# R40 register map
Vendor: Allwinner; Series: R40; File version: 0.1
CPU: CA7 0, little endian, MPU, FPU, double-precision FPU, 0 interrupt priority bits
Registers are 32-bit, read-write, reset 0x0 unless marked. A register's access mark holds for its fields unless they carry their own. Offsets are from the block's base; [hi:lo] are bit positions; {n}, {i} and the like mark numbered series; 'fields as' and 'values as' point back to an identical list.

## Timer
Base 0x01C20C00
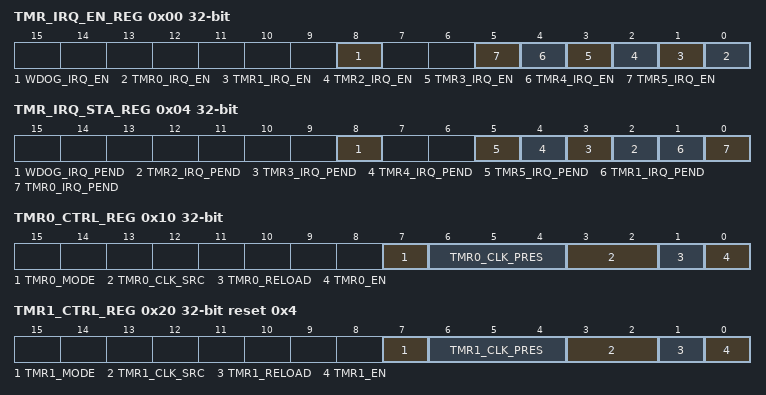
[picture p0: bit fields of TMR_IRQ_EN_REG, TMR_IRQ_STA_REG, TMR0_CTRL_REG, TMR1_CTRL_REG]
0x00 TMR_IRQ_EN_REG — Timer IRQ Enable Register
  [8] WDOG_IRQ_EN — Watchdog Interrupt Enable. 0: No effect 1: Watchdog Interval Value reached interrupt enable.
    0=No_effect; 1=Watchdog Interval Value reached interrupt enable
  [n] TMR{n}_IRQ_EN (n=0..5) — Timer {n} Interrupt Enable. 0: No effect 1: Timer {n} Interval Value reached interrupt enable.
    0=No_effect; 1=Timer {n} Interval Value reached interrupt enable
0x04 TMR_IRQ_STA_REG reset not defined — 0x0004 Timer Status Register
  [8] WDOG_IRQ_PEND write-1-clears — 0x0 WDOG_IRQ_PEND. Watchdog IRQ Pending. Setting 1 to the bit will clear it. 0: No effect 1: Pending, Watchdog counter value is reached.
    0=No_effect; 1=Pending, Watchdog counter value is reached
  [n] TMR{n}_IRQ_PEND write-1-clears (n=2..5) — 0x0 TMR{n}_IRQ_PEND. Timer {n} IRQ Pending. Setting 1 to the bit will clear it. 0: No effect 1: Pending, timer {n} counter value is reached.
    0=No_effect; 1=Pending, timer {n} counter value is reached
  [1] TMR1_IRQ_PEND write-1-clears — 0x0 TMR1_IRQ_PEND. Timer 1 IRQ Pending. Setting 1 to the bit will clear it. 0: No effect 1: Pending, timer 1 interval value is reached.
    0=No_effect; 1=Pending, timer 1 interval value is reached
  [0] TMR0_IRQ_PEND write-1-clears — 0x0 TMR0_IRQ_PEND. Timer 0 IRQ Pending. Setting 1 to the bit will clear it. 0: No effect 1: Pending, timer 0 interval value is reached.
    0=No_effect; 1=Pending, timer 0 interval value is reached
0x10 TMR0_CTRL_REG reset not defined — 0x0010 Timer 0 Control Register
  [7] TMR0_MODE — 0x0 TMR0_MODE. Timer 0 mode. 0: Continuous mode. When interval value reached, the timer will not disable automatically. 1: Single mode. When interval value reached, the timer will disable automatically.
    0=Continuous mode. When interval value reached, the timer will not disable automatically.; 1=Single mode. When interval value reached, the timer will disable automatically.
  [6:4] TMR0_CLK_PRES — 0x0 TMR0_CLK_PRES. Select the pre-scale of timer 0 clock source. 000: /1 001: /2 010: /4 011: /8 100: /16 101: /32 110: /64 111: /128
    0=_slash_1 (/1); 1=_slash_2 (/2); 2=_slash_4 (/4); 3=_slash_8 (/8); 4=_slash_16 (/16); 5=_slash_32 (/32); 6=_slash_64 (/64); 7=_slash_128 (/128)
  [3:2] TMR0_CLK_SRC — 0x1 TMR0_CLK_SRC. Timer 0 Clock Source. 00: Low speed OSC, 01: OSC24M. 10: PLL_PERIPH0_1X/36 11: /.
    0=Low (Low speed OSC,); 1=OSC24M; 2=PLL_PERIPH0_1X_slash_36 (PLL_PERIPH0_1X/36); 3=_slash_
  [1] TMR0_RELOAD — 0x0 TMR0_RELOAD. Timer 0 Reload. 0: No effect 1: Reload timer 0 Interval value.
    0=No_effect; 1=Reload timer 0 Interval value
  [0] TMR0_EN — 0x0 TMR0_EN. Timer 0 Enable. 0: Stop/Pause 1: Start. If the timer is started, it will reload the interval value to internal register, and the current counter will count from interval value to 0. If the current counter does not reach the zero, the timer enable bit is set to `0`, the current value counter will pause. At least wait for 2 Tcylces, the start bit can be set to 1. In timer pause state, the interval value register can be modified. If the timer is started again, and the Software hope the current value register to down-count from the new interval value, the reload bit and the enable bit should be set to 1 at the same time.
    0=Stop_slash_Pause (Stop/Pause); 1=Start. If the timer is started, it will reload the interval value to internal register, and the current counter will count from interval value to 0. If the current counter does not reach the zero, the timer enable bit is set to `0`, the current value counter will pause. At least wait for 2 Tcylces, the start bit can be set to 1. In timer pause state, the interval value register can be modified. If the timer is started again, and the Software hope the current value register to down-count from the new interval value, the reload bit and the enable bit should be set to 1 at the same time.
{0x14+0x10*i} TMR{i}_INTV_VALUE_REG (i=0..5) — {0x14+0x10*i} Timer {i} Interval Value Register
  [31:0] TMR{i}_INTV_VALUE — Timer {i} Interval Value.
{0x18+0x10*i} TMR{i}_CUR_VALUE_REG (i=0..2) — {0x18+0x10*i} Timer {i} Current Value Register
  [31:0] TMR{i}_CUR_VALUE — Timer {i} Current Value.
0x20 TMR1_CTRL_REG reset 0x4 — 0x0020 Timer 1 Control Register
  [7] TMR1_MODE — Timer 1 mode. 0: Continuous mode. When interval value reached, the timer will not disable automatically. 1: Single mode. When interval value reached, the timer will disable automatically.
    values as TMR0_CTRL_REG.TMR0_MODE
  [6:4] TMR1_CLK_PRES — Select the pre-scale of timer 1 clock source. 000: /1 001: /2 010: /4 011: /8 100: /16 101: /32 110: /64 111: /128
    values as TMR0_CTRL_REG.TMR0_CLK_PRES
  [3:2] TMR1_CLK_SRC — Timer 1 Clock Source. 00: Low speed OSC 01: OSC24M. 10: PLL6/6 11: /.
    0=Low (Low speed OSC); 1=OSC24M; 2=PLL6_slash_6 (PLL6/6); 3=_slash_
  [1] TMR1_RELOAD — Timer 1 Reload. 0: No effect 1: Reload timer 1 Interval value.
    0=No_effect; 1=Reload timer 1 Interval value
  [0] TMR1_EN — Timer 1 Enable. 0: Stop/Pause 1: Start. If the timer is started, it will reload the interval value to internal register, and the current counter will count from interval value to 0. If the current counter does not reach the zero, the timer enable bit is set to `0`, the current value counter will pause. At least wait for 2 Tcylces, the start bit can be set to 1. In timer pause state, the interval value register can be modified. If the timer is started again, and the Software hope the current value register to down-count from the new interval value, the reload bit and the enable bit should be set to 1 at the same time.
    values as TMR0_CTRL_REG.TMR0_EN
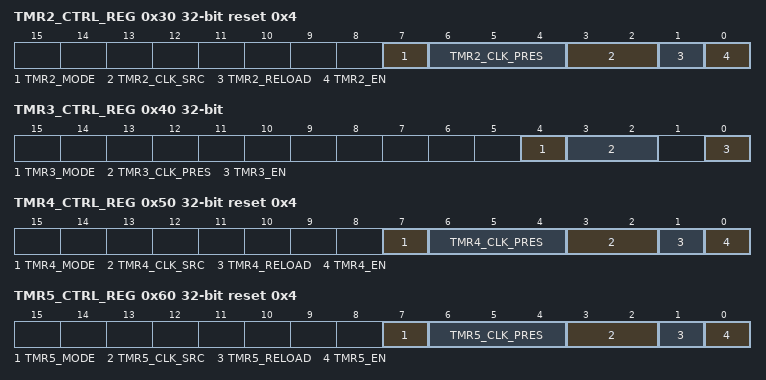
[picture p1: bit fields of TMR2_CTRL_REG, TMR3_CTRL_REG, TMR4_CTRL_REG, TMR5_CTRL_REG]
0x30 TMR2_CTRL_REG reset 0x4 — 0x0030 Timer 2 Control Register
  [7] TMR2_MODE — Timer 2 mode. 0: Continuous mode. When interval value reached, the timer will not disable automatically. 1: Single mode. When interval value reached, the timer will disable automatically.
    values as TMR0_CTRL_REG.TMR0_MODE
  [6:4] TMR2_CLK_PRES — Select the pre-scale of timer 2 clock source. 000: /1 001: /2 010: /4 011: /8 100: /16 101: /32 110: /64 111: /128
    values as TMR0_CTRL_REG.TMR0_CLK_PRES
  [3:2] TMR2_CLK_SRC — Timer 2 Clock Source. 00: Low speed OSC 01: OSC24M. 1x: /.
    0=Low (Low speed OSC); 1=OSC24M; 2=_slash_
  [1] TMR2_RELOAD — Timer 2 Reload. 0: No effect 1: Reload timer 2 Interval value.
    0=No_effect; 1=Reload timer 2 Interval value
  [0] TMR2_EN — Timer 2 Enable. 0: Stop/Pause 1: Start. If the timer is started, it will reload the interval value to internal register, and the current counter will count from interval value to 0. If the current counter does not reach the zero, the timer enable bit is set to `0`, the current value counter will pause. At least wait for 2 Tcylces, the start bit can be set to 1. In timer pause state, the interval value register can be modified. If the timer is started again, and the Software hope the current value register to down-count from the new interval value, the reload bit and the enable bit should be set to 1 at the same time.
    values as TMR0_CTRL_REG.TMR0_EN
0x40 TMR3_CTRL_REG — 0x0040 Timer 3 Control Register
  [4] TMR3_MODE — Timer 3 mode. 0: Continuous mode. When interval value reached, the timer will not disable automatically. 1: Single mode. When interval value reached, the timer will disable automatically.
    values as TMR0_CTRL_REG.TMR0_MODE
  [3:2] TMR3_CLK_PRES — Select the pre-scale of timer 3 clock source. Timer 3 clock source is the LOSC. 00: /16 01: /32 10: /64 11: /
    0=_slash_16 (/16); 1=_slash_32 (/32); 2=_slash_64 (/64)
  [0] TMR3_EN — Timer 3 Enable. 0: Disable 1: Enable.
    0=Disable; 1=Enable
0x50 TMR4_CTRL_REG reset 0x4 — 0x0050 Timer 4 Control Register
  [7] TMR4_MODE — Timer 4 mode. 0: Continuous mode. When interval value reached, the timer will not disable automatically. 1: Single mode. When interval value reached, the timer will disable automatically.
    values as TMR0_CTRL_REG.TMR0_MODE
  [6:4] TMR4_CLK_PRES — Select the pre-scale of timer 4 clock source. 000: /1 001: /2 010: /4 011: /8 100: /16 101: /32 110: /64 111: /128
    values as TMR0_CTRL_REG.TMR0_CLK_PRES
  [3:2] TMR4_CLK_SRC — Timer 4 Clock Source. 00: Low speed OSC 01: OSC24M. 10: External CLKIN0 11: /.
    0=Low (Low speed OSC); 1=OSC24M; 2=External CLKIN0; 3=_slash_
  [1] TMR4_RELOAD — Timer 4 Reload. 0: No effect 1: Reload timer 4 Interval value.
    0=No_effect; 1=Reload timer 4 Interval value
  [0] TMR4_EN — Timer 4 Enable. 0: Stop/Pause 1: Start. If the timer is started, it will reload the interval value to internal register, and the current counter will count from interval value to 0. If the current counter does not reach the zero, the timer enable bit is set to `0`, the current value counter will pause. At least wait for 2 Tcylces, the start bit can be set to 1. In timer pause state, the interval value register can be modified. If the timer is started again, and the Software hope the current value register to down-count from the new interval value, the reload bit and the enable bit should be set to 1 at the same time.
    values as TMR0_CTRL_REG.TMR0_EN
0x58 TMR4_CUR_VALUE_REG — 0x0058 Timer 4 Current Value Register
  [31:0] TMR4_CUR_VALUE — Timer 4 Current Value.
0x60 TMR5_CTRL_REG reset 0x4 — 0x0060 Timer 5 Control Register
  [7] TMR5_MODE — Timer 5 mode. 0: Continuous mode. When interval value reached, the timer will not disable automatically. 1: Single mode. When interval value reached, the timer will disable automatically.
    values as TMR0_CTRL_REG.TMR0_MODE
  [6:4] TMR5_CLK_PRES — Select the pre-scale of timer 5 clock source. 000: /1 001: /2 010: /4 011: /8 100: /16 101: /32 110: /64 111: /128
    values as TMR0_CTRL_REG.TMR0_CLK_PRES
  [3:2] TMR5_CLK_SRC — Timer 5 Clock Source. 00: Low speed OSC 01: OSC24M. 10: External CLKIN1 11: /.
    0=Low (Low speed OSC); 1=OSC24M; 2=External CLKIN1; 3=_slash_
  [1] TMR5_RELOAD — Timer 5 Reload. 0: No effect 1: Reload timer 5 Interval value.
    0=No_effect; 1=Reload timer 5 Interval value
  [0] TMR5_EN — Timer 5 Enable. 0: Stop/Pause 1: Start. If the timer is started, it will reload the interval value to internal register, and the current counter will count from interval value to 0. If the current counter does not reach the zero, the timer enable bit is set to `0`, the current value counter will pause. At least wait for 2 Tcylces, the start bit can be set to 1. In timer pause state, the interval value register can be modified. If the timer is started again, and the Software hope the current value register to down-count from the new interval value, the reload bit and the enable bit should be set to 1 at the same time.
    values as TMR0_CTRL_REG.TMR0_EN
0x68 TMR5_CUR_VALUE_REG — 0x0068 Timer 5 Current Value Register
  [31:0] TMR5_CUR_VALUE — Timer 5 Current Value.
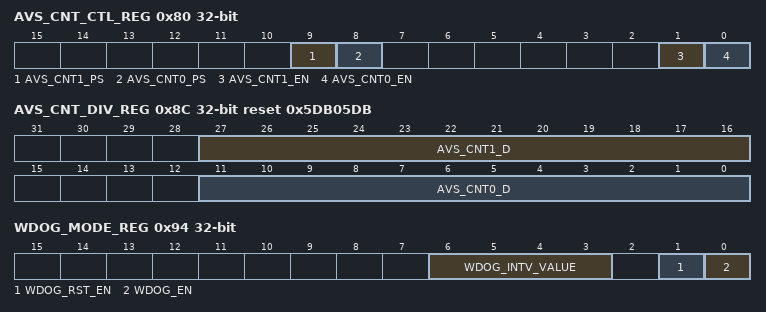
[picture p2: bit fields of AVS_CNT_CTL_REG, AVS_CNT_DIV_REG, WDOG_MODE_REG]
0x80 AVS_CNT_CTL_REG — 0x0080 AVS Control Register
  [9] AVS_CNT1_PS ro — Audio/Video Sync Counter 1 Pause Control 0: Not pause 1: Pause Counter 1
    0=Not_pause; 1=Pause Counter 1
  [8] AVS_CNT0_PS — Audio/Video Sync Counter 0 Pause Control 0: Not pause 1: Pause Counter 0
    0=Not_pause; 1=Pause Counter 0
  [1] AVS_CNT1_EN — Audio/Video Sync Counter 1 Enable/Disable. The counter source is OSC24M. 0: Disable 1: Enable
    0=Disable; 1=Enable
  [0] AVS_CNT0_EN — Audio/Video Sync Counter 1 Enable/Disable. The counter source is OSC24M. 0: Disable 1: Enable
    0=Disable; 1=Enable
0x84 AVS_CNT0_REG — 0x0084 AVS Counter 0 Register
  [31:0] AVS_CNT0 — Counter 0 for Audio/ Video Sync Application The high 32 bits of the internal 33-bits counter register. The initial value of the internal 33-bits counter register can be set by software. The LSB bit of the 33-bits counter register should be zero when the initial value is updated. It will count from the initial value. The initial value can be updated at any time. It can also be paused by setting to `1`. When it is paused, the counter won`t increase.
0x88 AVS_CNT1_REG — 0x0088 AVS Counter 1 Register
  [31:0] AVS_CNT1 — Counter 1 for Audio/ Video Sync Application The high 32 bits of the internal 33-bits counter register. The initial value of the internal 33-bits counter register can be set by software. The LSB bit of the 33-bits counter register should be zero when the initial value is updated. It will count from the initial value. The initial value can be updated at any time. It can also be paused by setting to `1`. When it is paused, the counter will not increase.
0x8C AVS_CNT_DIV_REG reset 0x5DB05DB — 0x008C AVS Divisor Register
  [27:16] AVS_CNT1_D — Divisor N for AVS Counter1 AVS CN1 CLK=24MHz/Divisor_N1. Divisor N1 = Bit[27:16] + 1. The number N is from 1 to 0x7ff. The zero value is reserved. The internal 33-bits counter engine will maintain another 12-bits counter. The 12-bits counter is used for counting the cycle number of one 24MHz clock. When the 12-bits counter reaches (>= N) the divisor value, the internal 33-bits counter register will increase 1 and the 12-bits counter will reset to zero and restart again. Notes: It can be configured by software at any time.
  [11:0] AVS_CNT0_D — Divisor N for AVS Counter0 AVS CN0 CLK=24MHz/Divisor_N0. Divisor N0 = Bit[11:0] + 1 The number N is from 1 to 0x7ff. The zero value is reserved. The internal 33-bits counter engine will maintain another 12-bits counter. The 12-bits counter is used for counting the cycle number of one 24MHz clock. When the 12-bits counter reaches (>= N) the divisor value, the internal 33-bits counter register will increase 1 and the 12-bits counter will reset to zero and restart again. Notes: It can be configured by software at any time.
0x90 WDOG_CTRL_REG — 0x0090 Watchdog Control Register
  [0] WDOG_RSTART — Watchdog Restart. 0: No effect 1: Restart the Watchdog.
    0=No_effect; 1=Restart the Watchdog
0x94 WDOG_MODE_REG — 0x0094 Watchdog Mode Register
  [6:3] WDOG_INTV_VALUE — Watchdog Interval Value Watchdog clock source is OSC24M. If the OSC24M is turned off, the watchdog will not work. 0000: 0.5sec 0001: 1sec 0010: 2sec 0011: 3sec 0100: 4sec 0101: 5sec 0110: 6sec 0111: 8sec 1000: 10sec 1001: 12sec 1010: 14sec 1011: 16sec 1100: / 1101: / 1110: / 1111: /
    0=_0_point_5sec (0.5sec); {v}=_{v}sec (v=1..6); 7=_8sec; 8=_10sec; 9=_12sec; 10=_14sec; 11=_16sec
  [1] WDOG_RST_EN — Watchdog Reset Enable. 0: No effect on the resets 1: Enables the Watchdog to activate the system reset.
    0=No effect on the resets; 1=Enables the Watchdog to activate the system reset
  [0] WDOG_EN — Watchdog Enable. 0: No effect 1: Enable the Watchdog.
    0=No_effect; 1=Enable the Watchdog
